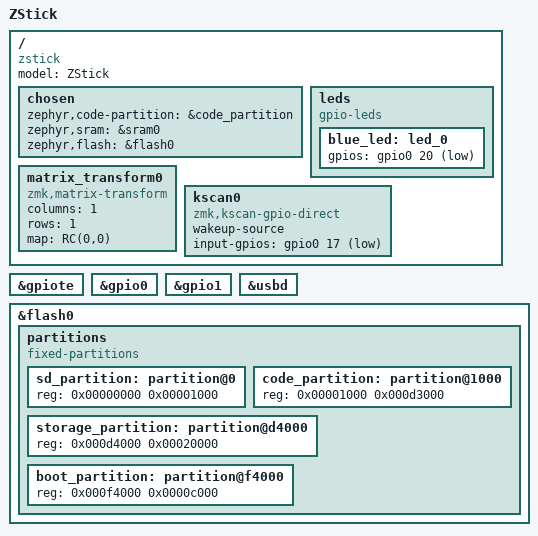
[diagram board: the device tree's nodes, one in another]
/*
Copyright (c) 2022 The ZMK Contributors

SPDX-License-Identifier: MIT
*/

/dts-v1/;

#include <nordic/nrf52840_qiaa.dtsi>

/ {
	model = "ZStick";
	compatible = "zstick";
	
	chosen {
		zephyr,code-partition = &code_partition;
		zephyr,sram = &sram0;
		zephyr,flash = &flash0;
	};
	
	leds {
		compatible = "gpio-leds";
		blue_led: led_0 {
			gpios = <&gpio0 20 GPIO_ACTIVE_LOW>;
		};
	};

matrix_transform0: matrix_transform0 {
        compatible = "zmk,matrix-transform";
        columns = <1>;
        rows = <1>;
        map = <
            RC(0,0)
        >;
    };

    kscan0: kscan0 {
        compatible = "zmk,kscan-gpio-direct";
        wakeup-source;

        input-gpios
            = <&gpio0 17 (GPIO_ACTIVE_LOW | GPIO_PULL_UP)>
            ;
    };
};

&gpiote {
	status = "okay";
};

&gpio0 {
	status = "okay";
};

&gpio1 {
	status = "okay";
};

zephyr_udc0: &usbd {
	status = "okay";
};

&flash0 {
	partitions {
		compatible = "fixed-partitions";
		#address-cells = <1>;
		#size-cells = <1>;
		
		sd_partition: partition@0 {
			reg = <0x00000000 0x00001000>;
		};
		
		code_partition: partition@1000 {
			reg = <0x00001000 0x000d3000>;
		};
		
		storage_partition: partition@d4000 {
			reg = <0x000d4000 0x00020000>;
		};
		
		boot_partition: partition@f4000 {
			reg = <0x000f4000 0x0000c000>;
		};
	};
};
